VERSION ""

NS_ :

BS_:

BU_: SENSOR FEATURE ASSISTANT MONITOR INJECTOR

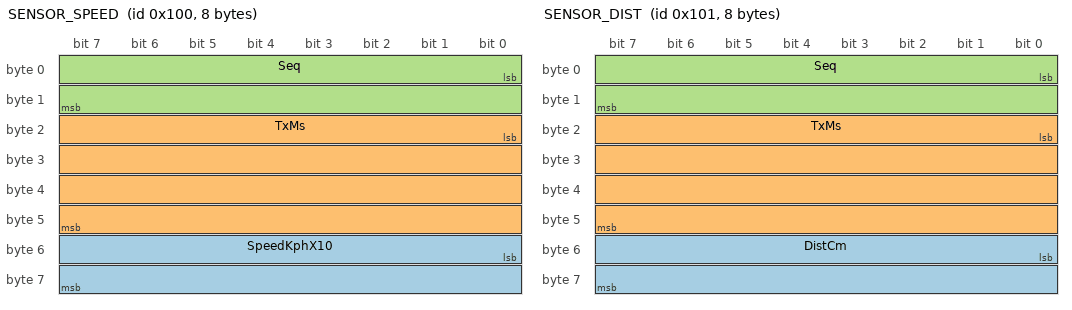
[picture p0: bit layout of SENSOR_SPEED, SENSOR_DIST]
BO_ 256 SENSOR_SPEED: 8 SENSOR
 SG_ SpeedKphX10 : 48|16@1+ (0.1,0) [0|6553.5] "km/h" FEATURE,MONITOR
 SG_ TxMs : 16|32@1+ (1,0) [0|4294967295] "ms" MONITOR
 SG_ Seq : 0|16@1+ (1,0) [0|65535] "" MONITOR

BO_ 257 SENSOR_DIST: 8 SENSOR
 SG_ DistCm : 48|16@1+ (1,0) [0|65535] "cm" FEATURE,MONITOR
 SG_ TxMs : 16|32@1+ (1,0) [0|4294967295] "ms" MONITOR
 SG_ Seq : 0|16@1+ (1,0) [0|65535] "" MONITOR

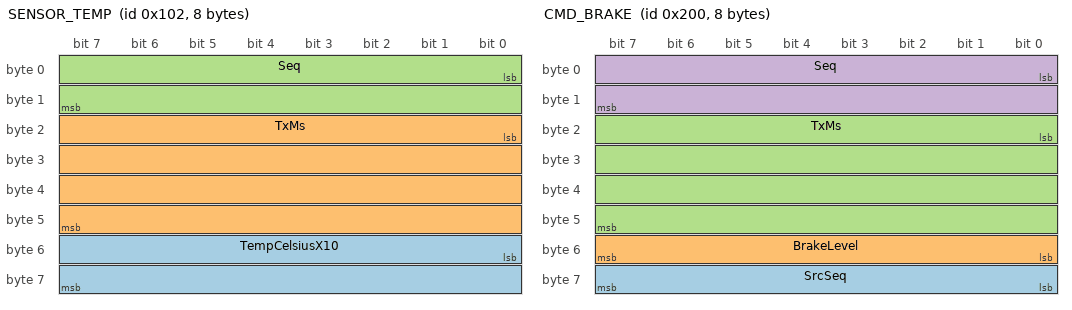
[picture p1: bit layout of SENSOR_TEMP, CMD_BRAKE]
BO_ 258 SENSOR_TEMP: 8 SENSOR
 SG_ TempCelsiusX10 : 48|16@1+ (0.1,0) [0|6553.5] "degC" MONITOR
 SG_ TxMs : 16|32@1+ (1,0) [0|4294967295] "ms" MONITOR
 SG_ Seq : 0|16@1+ (1,0) [0|65535] "" MONITOR

BO_ 512 CMD_BRAKE: 8 FEATURE
 SG_ SrcSeq : 56|8@1+ (1,0) [0|255] "" ASSISTANT,MONITOR
 SG_ BrakeLevel : 48|8@1+ (1,0) [0|100] "%" ASSISTANT,MONITOR
 SG_ TxMs : 16|32@1+ (1,0) [0|4294967295] "ms" MONITOR
 SG_ Seq : 0|16@1+ (1,0) [0|65535] "" MONITOR

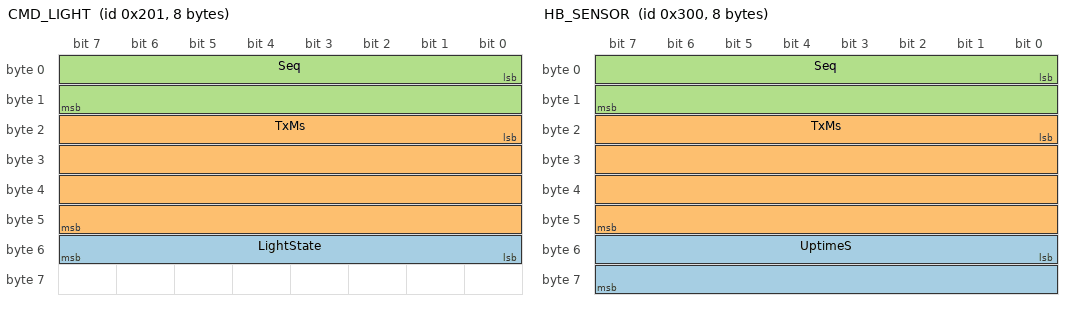
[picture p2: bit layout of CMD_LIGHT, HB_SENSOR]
BO_ 513 CMD_LIGHT: 8 FEATURE
 SG_ LightState : 48|8@1+ (1,0) [0|2] "" ASSISTANT,MONITOR
 SG_ TxMs : 16|32@1+ (1,0) [0|4294967295] "ms" MONITOR
 SG_ Seq : 0|16@1+ (1,0) [0|65535] "" MONITOR

BO_ 768 HB_SENSOR: 8 SENSOR
 SG_ UptimeS : 48|16@1+ (1,0) [0|65535] "s" MONITOR
 SG_ TxMs : 16|32@1+ (1,0) [0|4294967295] "ms" MONITOR
 SG_ Seq : 0|16@1+ (1,0) [0|65535] "" MONITOR

BO_ 769 HB_FEATURE: 8 FEATURE
 SG_ TxMs : 16|32@1+ (1,0) [0|4294967295] "ms" MONITOR
 SG_ Seq : 0|16@1+ (1,0) [0|65535] "" MONITOR

BO_ 770 HB_ASSISTANT: 8 ASSISTANT
 SG_ TxMs : 16|32@1+ (1,0) [0|4294967295] "ms" MONITOR
 SG_ Seq : 0|16@1+ (1,0) [0|65535] "" MONITOR

BO_ 1024 LOADGEN: 8 INJECTOR
 SG_ Seq : 0|16@1+ (1,0) [0|65535] "" MONITOR

BO_ 1280 PING: 8 MONITOR
 SG_ TxMs : 16|32@1+ (1,0) [0|4294967295] "ms" MONITOR
 SG_ Seq : 0|16@1+ (1,0) [0|65535] "" ASSISTANT

BO_ 1281 PONG: 8 ASSISTANT
 SG_ TxMs : 16|32@1+ (1,0) [0|4294967295] "ms" MONITOR
 SG_ Seq : 0|16@1+ (1,0) [0|65535] "" MONITOR

CM_ BU_ SENSOR "Simulated sensor ECU (ProcessingECU-like)";
CM_ BU_ FEATURE "Control-logic ECU (FeatureECU-like)";
CM_ BU_ ASSISTANT "Actuator/demo ECU (AssistantECU-like), answers PING";
CM_ BU_ MONITOR "Passive measurement node + active PING prober";
CM_ BU_ INJECTOR "Deterministic bus-load generator";
